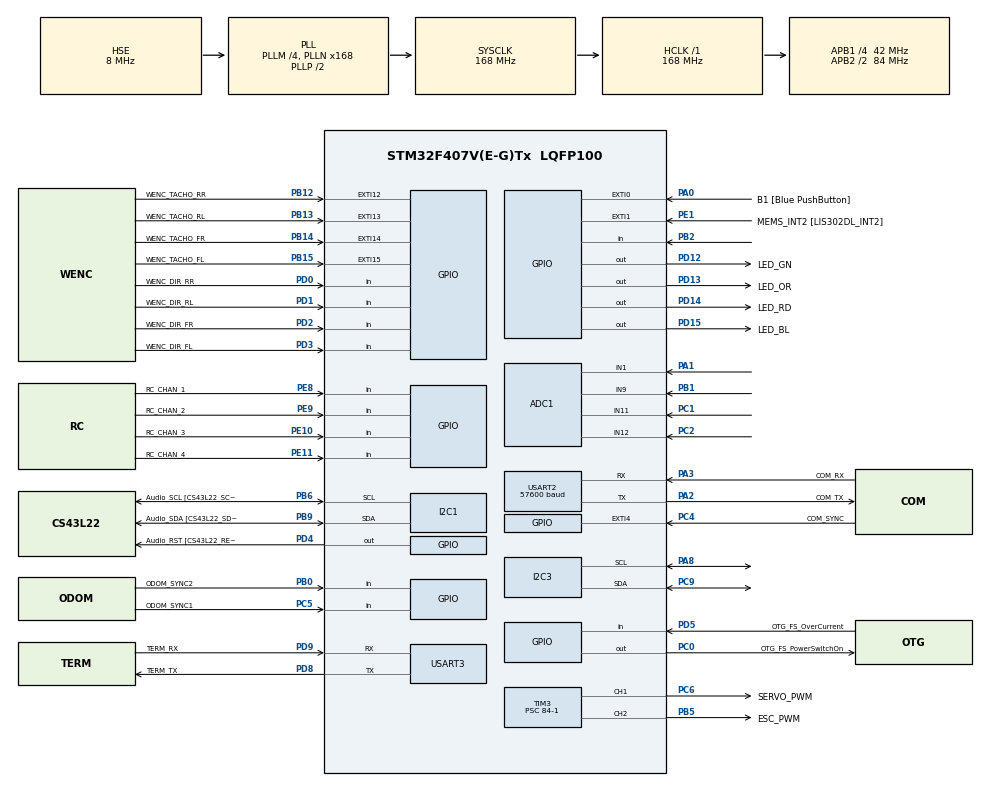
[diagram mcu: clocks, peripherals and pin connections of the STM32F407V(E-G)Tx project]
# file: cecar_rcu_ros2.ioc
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ADC1.Channel-0\#ChannelRegularConversion=ADC_CHANNEL_1
ADC1.NbrOfConversionFlag=1
ADC1.Rank-0\#ChannelRegularConversion=1
ADC1.SamplingTime-0\#ChannelRegularConversion=ADC_SAMPLETIME_3CYCLES
ADC1.master=1
Dma.Request0=USART2_RX
Dma.Request1=USART2_TX
Dma.USART2_RX.0.Direction=DMA_PERIPH_TO_MEMORY
Dma.USART2_RX.0.FIFOMode=DMA_FIFOMODE_DISABLE
Dma.USART2_RX.0.Instance=DMA1_Stream5
Dma.USART2_RX.0.MemDataAlignment=DMA_MDATAALIGN_BYTE
Dma.USART2_RX.0.MemInc=DMA_MINC_ENABLE
Dma.USART2_RX.0.Mode=DMA_CIRCULAR
Dma.USART2_RX.0.PeriphDataAlignment=DMA_PDATAALIGN_BYTE
Dma.USART2_RX.0.PeriphInc=DMA_PINC_DISABLE
Dma.USART2_RX.0.Priority=DMA_PRIORITY_LOW
Dma.USART2_TX.1.Direction=DMA_MEMORY_TO_PERIPH
Dma.USART2_TX.1.FIFOMode=DMA_FIFOMODE_DISABLE
Dma.USART2_TX.1.Instance=DMA1_Stream6
Dma.USART2_TX.1.MemDataAlignment=DMA_MDATAALIGN_BYTE
Dma.USART2_TX.1.MemInc=DMA_MINC_ENABLE
Dma.USART2_TX.1.Mode=DMA_NORMAL
Dma.USART2_TX.1.PeriphDataAlignment=DMA_PDATAALIGN_BYTE
Dma.USART2_TX.1.PeriphInc=DMA_PINC_DISABLE
Dma.USART2_TX.1.Priority=DMA_PRIORITY_LOW
I2C1.I2C_Mode=I2C_Fast
I2C3.I2C_Mode=I2C_Fast
Mcu.Family=STM32F4
Mcu.Name=STM32F407V(E-G)Tx
Mcu.Package=LQFP100
NVIC.DMA1_Stream5_IRQn=true\:0\:0\:false\:false\:true\:false\:true
NVIC.DMA1_Stream6_IRQn=true\:0\:0\:false\:false\:true\:false\:true
NVIC.EXTI15_10_IRQn=true\:0\:0\:false\:false\:true\:true\:true
NVIC.PriorityGroup=NVIC_PRIORITYGROUP_0
NVIC.TIM2_IRQn=true\:0\:0\:false\:false\:true\:true\:true
PA0-WKUP.GPIO_Label=B1 [Blue PushButton]
PA0-WKUP.Signal=GPXTI0
PA1.Signal=ADCx_IN1
PA10.GPIO_Label=OTG_FS_ID
PA10.GPIO_Mode=GPIO_MODE_AF_PP
PA10.GPIO_PuPd=GPIO_NOPULL
PA10.GPIO_Speed=GPIO_SPEED_FREQ_LOW
PA10.Signal=USB_OTG_FS_ID
PA11.GPIO_Label=OTG_FS_DM
PA11.GPIO_Mode=GPIO_MODE_AF_PP
PA11.GPIO_PuPd=GPIO_NOPULL
PA11.GPIO_Speed=GPIO_SPEED_FREQ_LOW
PA11.Signal=USB_OTG_FS_DM
PA12.GPIO_Label=OTG_FS_DP
PA12.GPIO_Mode=GPIO_MODE_AF_PP
PA12.GPIO_PuPd=GPIO_NOPULL
PA12.GPIO_Speed=GPIO_SPEED_FREQ_LOW
PA12.Signal=USB_OTG_FS_DP
PA13.GPIO_Label=SWDIO
PA13.Mode=Trace_Asynchronous_SW
PA13.Signal=SYS_JTMS-SWDIO
PA14.GPIO_Label=SWCLK
PA14.Mode=Trace_Asynchronous_SW
PA14.Signal=SYS_JTCK-SWCLK
PA2.GPIO_Label=COM_TX
PA2.Mode=Asynchronous
PA2.Signal=USART2_TX
PA3.GPIO_Label=COM_RX
PA3.Mode=Asynchronous
PA3.Signal=USART2_RX
PA4.GPIO_Label=I2S3_WS [CS43L22_LRCK]
PA4.GPIO_Mode=GPIO_MODE_AF_PP
PA4.GPIO_PuPd=GPIO_NOPULL
PA4.GPIO_Speed=GPIO_SPEED_FREQ_LOW
PA4.Signal=I2S3_WS
PA5.GPIO_Label=SPI1_SCK [LIS302DL_SCL/SPC]
PA5.GPIO_Mode=GPIO_MODE_AF_PP
PA5.GPIO_PuPd=GPIO_NOPULL
PA5.GPIO_Speed=GPIO_SPEED_FREQ_LOW
PA5.Signal=SPI1_SCK
PA6.GPIO_Label=SPI1_MISO [LIS302DL_SDO]
PA6.GPIO_Mode=GPIO_MODE_AF_PP
PA6.GPIO_PuPd=GPIO_NOPULL
PA6.GPIO_Speed=GPIO_SPEED_FREQ_LOW
PA6.Signal=SPI1_MISO
PA7.GPIO_Label=SPI1_MOSI [LIS302DL_SDA/SDI/SDO]
PA7.GPIO_Mode=GPIO_MODE_AF_PP
PA7.GPIO_PuPd=GPIO_NOPULL
PA7.GPIO_Speed=GPIO_SPEED_FREQ_LOW
PA7.Signal=SPI1_MOSI
PA8.Mode=I2C
PA8.Signal=I2C3_SCL
PA9.GPIO_Label=VBUS_FS
PA9.GPIO_Mode=GPIO_MODE_INPUT
PA9.GPIO_PuPd=GPIO_NOPULL
PA9.Signal=USB_OTG_FS_VBUS
PB0.GPIO_Label=ODOM_SYNC2
PB0.Signal=GPIO_Input
PB1.Signal=ADCx_IN9
PB10.GPIO_Label=CLK_IN [MP45DT02_CLK]
PB10.GPIO_Mode=GPIO_MODE_AF_PP
PB10.GPIO_PuPd=GPIO_NOPULL
PB10.GPIO_Speed=GPIO_SPEED_FREQ_LOW
PB10.Signal=I2S2_CK
PB12.GPIO_Label=WENC_TACHO_RR
PB12.Signal=GPXTI12
PB13.GPIO_Label=WENC_TACHO_RL
PB13.Signal=GPXTI13
PB14.GPIO_Label=WENC_TACHO_FR
PB14.Signal=GPXTI14
PB15.GPIO_Label=WENC_TACHO_FL
PB15.Signal=GPXTI15
PB2.Signal=GPIO_Input
PB3.GPIO_Label=SWO
PB3.Mode=Trace_Asynchronous_SW
PB3.Signal=SYS_JTDO-SWO
PB5.GPIO_Label=ESC_PWM
PB5.Signal=S_TIM3_CH2
PB6.GPIO_Label=Audio_SCL [CS43L22_SCL]
PB6.GPIO_Mode=GPIO_MODE_AF_OD
PB6.GPIO_PuPd=GPIO_NOPULL
PB6.GPIO_Speed=GPIO_SPEED_FREQ_LOW
PB6.Mode=I2C
PB6.Signal=I2C1_SCL
PB9.GPIO_Label=Audio_SDA [CS43L22_SDA]
PB9.GPIO_Mode=GPIO_MODE_AF_OD
PB9.GPIO_PuPd=GPIO_NOPULL
PB9.GPIO_Speed=GPIO_SPEED_FREQ_LOW
PB9.Mode=I2C
PB9.Signal=I2C1_SDA
PC0.GPIO_Label=OTG_FS_PowerSwitchOn
PC0.GPIO_PuPd=GPIO_NOPULL
PC0.GPIO_Speed=GPIO_SPEED_FREQ_LOW
PC0.PinState=GPIO_PIN_SET
PC0.Signal=GPIO_Output
PC1.Signal=ADCx_IN11
PC10.GPIO_Label=I2S3_SCK [CS43L22_SCLK]
PC10.GPIO_Mode=GPIO_MODE_AF_PP
PC10.GPIO_PuPd=GPIO_NOPULL
PC10.GPIO_Speed=GPIO_SPEED_FREQ_LOW
PC10.Signal=I2S3_CK
PC12.GPIO_Label=I2S3_SD [CS43L22_SDIN]
PC12.GPIO_Mode=GPIO_MODE_AF_PP
PC12.GPIO_PuPd=GPIO_NOPULL
PC12.GPIO_Speed=GPIO_SPEED_FREQ_LOW
PC12.Signal=I2S3_SD
PC14-OSC32_IN.GPIO_Label=PC14-OSC32_IN
PC14-OSC32_IN.Signal=RCC_OSC32_IN
PC15-OSC32_OUT.GPIO_Label=PC15-OSC32_OUT
PC15-OSC32_OUT.Signal=RCC_OSC32_OUT
PC2.Signal=ADCx_IN12
PC3.GPIO_Label=PDM_OUT [MP45DT02_DOUT]
PC3.GPIO_Mode=GPIO_MODE_AF_PP
PC3.GPIO_PuPd=GPIO_NOPULL
PC3.GPIO_Speed=GPIO_SPEED_FREQ_LOW
PC3.Signal=I2S2_SD
PC4.GPIO_Label=COM_SYNC
PC4.Signal=GPXTI4
PC5.GPIO_Label=ODOM_SYNC1
PC5.Signal=GPIO_Input
PC6.GPIO_Label=SERVO_PWM
PC6.Signal=S_TIM3_CH1
PC7.GPIO_Label=I2S3_MCK [CS43L22_MCLK]
PC7.GPIO_Mode=GPIO_MODE_AF_PP
PC7.GPIO_PuPd=GPIO_NOPULL
PC7.GPIO_Speed=GPIO_SPEED_FREQ_LOW
PC7.Signal=I2S3_MCK
PC9.Mode=I2C
PC9.Signal=I2C3_SDA
PD0.GPIO_Label=WENC_DIR_RR
PD0.Signal=GPIO_Input
PD1.GPIO_Label=WENC_DIR_RL
PD1.Signal=GPIO_Input
PD12.GPIO_Label=LED_GN
PD12.Signal=GPIO_Output
PD13.GPIO_Label=LED_OR
PD13.Signal=GPIO_Output
PD14.GPIO_Label=LED_RD
PD14.Signal=GPIO_Output
PD15.GPIO_Label=LED_BL
PD15.Signal=GPIO_Output
PD2.GPIO_Label=WENC_DIR_FR
PD2.Signal=GPIO_Input
PD3.GPIO_Label=WENC_DIR_FL
PD3.Signal=GPIO_Input
PD4.GPIO_Label=Audio_RST [CS43L22_RESET]
PD4.GPIO_PuPd=GPIO_NOPULL
PD4.GPIO_Speed=GPIO_SPEED_FREQ_LOW
PD4.Signal=GPIO_Output
PD5.GPIO_Label=OTG_FS_OverCurrent
PD5.GPIO_Mode=GPIO_MODE_INPUT
PD5.GPIO_PuPd=GPIO_NOPULL
PD5.Signal=GPIO_Input
PD8.GPIO_Label=TERM_TX
PD8.Mode=Asynchronous
PD8.Signal=USART3_TX
PD9.GPIO_Label=TERM_RX
PD9.Mode=Asynchronous
PD9.Signal=USART3_RX
PE1.GPIO_Label=MEMS_INT2 [LIS302DL_INT2]
PE1.GPIO_ModeDefaultEXTI=GPIO_MODE_EVT_RISING
PE1.GPIO_PuPd=GPIO_NOPULL
PE1.Signal=GPXTI1
PE10.GPIO_Label=RC_CHAN_3
PE10.Signal=GPIO_Input
PE11.GPIO_Label=RC_CHAN_4
PE11.Signal=GPIO_Input
PE8.GPIO_Label=RC_CHAN_1
PE8.Signal=GPIO_Input
PE9.GPIO_Label=RC_CHAN_2
PE9.Signal=GPIO_Input
PH0-OSC_IN.GPIO_Label=PH0-OSC_IN
PH0-OSC_IN.Mode=HSE-External-Oscillator
PH0-OSC_IN.Signal=RCC_OSC_IN
PH1-OSC_OUT.GPIO_Label=PH1-OSC_OUT
PH1-OSC_OUT.Mode=HSE-External-Oscillator
PH1-OSC_OUT.Signal=RCC_OSC_OUT
ProjectManager.HeapSize=0x200
ProjectManager.StackSize=0x400
ProjectManager.TargetToolchain=STM32CubeIDE
RCC.48MHZClocksFreq_Value=48000000
RCC.AHBFreq_Value=168000000
RCC.APB1CLKDivider=RCC_HCLK_DIV4
RCC.APB1Freq_Value=42000000
RCC.APB1TimFreq_Value=84000000
RCC.APB2CLKDivider=RCC_HCLK_DIV2
RCC.APB2Freq_Value=84000000
RCC.APB2TimFreq_Value=168000000
RCC.CortexFreq_Value=168000000
RCC.HCLKFreq_Value=168000000
RCC.HSE_VALUE=8000000
RCC.HSI_VALUE=16000000
RCC.LSE_VALUE=32768
RCC.PLLM=4
RCC.PLLN=168
RCC.PLLQ=7
RCC.PLLSourceVirtual=RCC_PLLSOURCE_HSE
RCC.SYSCLKFreq_VALUE=168000000
RCC.SYSCLKSource=RCC_SYSCLKSOURCE_PLLCLK
RCC.VCOOutputFreq_Value=336000000
SH.ADCx_IN1.0=ADC1_IN1,IN1
SH.ADCx_IN11.0=ADC1_IN11,IN11
SH.ADCx_IN12.0=ADC1_IN12,IN12
SH.ADCx_IN9.0=ADC1_IN9,IN9
SH.S_TIM3_CH1.0=TIM3_CH1,PWM Generation1 CH1
SH.S_TIM3_CH2.0=TIM3_CH2,PWM Generation2 CH2
TIM2.Channel-Output\ Compare1\ No\ Output=TIM_CHANNEL_1
TIM2.Period=100000-1
TIM2.Prescaler=84-1
TIM2.TIM_MasterOutputTrigger=TIM_TRGO_OC1
TIM2.TIM_MasterSlaveMode=TIM_MASTERSLAVEMODE_ENABLE
TIM3.Channel-PWM\ Generation1\ CH1=TIM_CHANNEL_1
TIM3.Channel-PWM\ Generation2\ CH2=TIM_CHANNEL_2
TIM3.Period=19999
TIM3.Prescaler=84-1
TIM3.Pulse-PWM\ Generation2\ CH2=1500
USART2.BaudRate=57600
USART2.VirtualMode=VM_ASYNC
USART3.VirtualMode=VM_ASYNC
VP_TIM2_VS_ClockSourceINT.Mode=Internal
VP_TIM2_VS_no_output1.Mode=Output Compare1 No Output
board=STM32F407G-DISC1

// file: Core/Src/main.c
/* USER CODE BEGIN Header */
/**
  ******************************************************************************
  * @file           : main.c
  * @brief          : Main program body
  ******************************************************************************
  * @attention
  *
  * <h2><center>&copy; Copyright (c) 2019 STMicroelectronics.
  * All rights reserved.</center></h2>
  *
  * This software component is licensed by ST under BSD 3-Clause license,
  * the "License"; You may not use this file except in compliance with the
  * License. You may obtain a copy of the License at:
  *                        opensource.org/licenses/BSD-3-Clause
  *
  ******************************************************************************
  */
/* USER CODE END Header */

#include "main.h"

/* USER CODE BEGIN Includes */
#include <main_cpp.h>
/* USER CODE END Includes */

ADC_HandleTypeDef hadc1;

I2C_HandleTypeDef hi2c1;
I2C_HandleTypeDef hi2c3;

TIM_HandleTypeDef htim2;
TIM_HandleTypeDef htim3;

UART_HandleTypeDef huart2;
UART_HandleTypeDef huart3;
DMA_HandleTypeDef hdma_usart2_rx;
DMA_HandleTypeDef hdma_usart2_tx;

void SystemClock_Config(void);
static void MX_GPIO_Init(void);
static void MX_DMA_Init(void);
static void MX_ADC1_Init(void);
static void MX_TIM2_Init(void);
static void MX_TIM3_Init(void);
static void MX_USART2_UART_Init(void);
static void MX_USART3_UART_Init(void);
static void MX_I2C1_Init(void);
static void MX_I2C3_Init(void);

/* USER CODE BEGIN 0 */

// for SWO debugging, see http://stefanfrings.de/stm32/cube_ide.html
int __io_putchar(char ch)
{
	return ITM_SendChar(ch);
}
/* USER CODE END 0 */

int main(void)
{
  /* USER CODE BEGIN 1 */
	// for easier timer debugging
#if 0
	__HAL_DBGMCU_FREEZE_TIM1();
	__HAL_DBGMCU_FREEZE_TIM2();
	__HAL_DBGMCU_FREEZE_TIM3();
	__HAL_DBGMCU_FREEZE_TIM4();
#endif
  /* USER CODE END 1 */

  /* MCU Configuration--------------------------------------------------------*/

  /* Reset of all peripherals, Initializes the Flash interface and the Systick. */
  HAL_Init();

  /* Configure the system clock */
  SystemClock_Config();

  /* Initialize all configured peripherals */
  MX_GPIO_Init();
  MX_DMA_Init();
  MX_ADC1_Init();
  MX_TIM2_Init();
  MX_TIM3_Init();
  MX_USART2_UART_Init();
  MX_USART3_UART_Init();
  MX_I2C1_Init();
  MX_I2C3_Init();
  /* USER CODE BEGIN 2 */
  setup(&huart2);
  /* USER CODE END 2 */

  /* Infinite loop */
  /* USER CODE BEGIN WHILE */
  while (1)
  {
	  loop(&huart2, &hdma_usart2_rx);
    /* USER CODE END WHILE */

  }
}

void SystemClock_Config(void)
{
  RCC_OscInitTypeDef RCC_OscInitStruct = {0};
  RCC_ClkInitTypeDef RCC_ClkInitStruct = {0};

  /** Configure the main internal regulator output voltage
  */
  __HAL_RCC_PWR_CLK_ENABLE();
  __HAL_PWR_VOLTAGESCALING_CONFIG(PWR_REGULATOR_VOLTAGE_SCALE1);
  /** Initializes the CPU, AHB and APB busses clocks
  */
  RCC_OscInitStruct.OscillatorType = RCC_OSCILLATORTYPE_HSE;
  RCC_OscInitStruct.HSEState = RCC_HSE_ON;
  RCC_OscInitStruct.PLL.PLLState = RCC_PLL_ON;
  RCC_OscInitStruct.PLL.PLLSource = RCC_PLLSOURCE_HSE;
  RCC_OscInitStruct.PLL.PLLM = 4;
  RCC_OscInitStruct.PLL.PLLN = 168;
  RCC_OscInitStruct.PLL.PLLP = RCC_PLLP_DIV2;
  RCC_OscInitStruct.PLL.PLLQ = 7;
  if (HAL_RCC_OscConfig(&RCC_OscInitStruct) != HAL_OK)
  {
    Error_Handler();
  }
  /** Initializes the CPU, AHB and APB busses clocks
  */
  RCC_ClkInitStruct.ClockType = RCC_CLOCKTYPE_HCLK|RCC_CLOCKTYPE_SYSCLK
                              |RCC_CLOCKTYPE_PCLK1|RCC_CLOCKTYPE_PCLK2;
  RCC_ClkInitStruct.SYSCLKSource = RCC_SYSCLKSOURCE_PLLCLK;
  RCC_ClkInitStruct.AHBCLKDivider = RCC_SYSCLK_DIV1;
  RCC_ClkInitStruct.APB1CLKDivider = RCC_HCLK_DIV4;
  RCC_ClkInitStruct.APB2CLKDivider = RCC_HCLK_DIV2;

  if (HAL_RCC_ClockConfig(&RCC_ClkInitStruct, FLASH_LATENCY_5) != HAL_OK)
  {
    Error_Handler();
  }
}

static void MX_ADC1_Init(void)
{

  ADC_ChannelConfTypeDef sConfig = {0};

  /** Configure the global features of the ADC (Clock, Resolution, Data Alignment and number of conversion)
  */
  hadc1.Instance = ADC1;
  hadc1.Init.ClockPrescaler = ADC_CLOCK_SYNC_PCLK_DIV4;
  hadc1.Init.Resolution = ADC_RESOLUTION_12B;
  hadc1.Init.ScanConvMode = DISABLE;
  hadc1.Init.ContinuousConvMode = DISABLE;
  hadc1.Init.DiscontinuousConvMode = DISABLE;
  hadc1.Init.ExternalTrigConvEdge = ADC_EXTERNALTRIGCONVEDGE_NONE;
  hadc1.Init.ExternalTrigConv = ADC_SOFTWARE_START;
  hadc1.Init.DataAlign = ADC_DATAALIGN_RIGHT;
  hadc1.Init.NbrOfConversion = 1;
  hadc1.Init.DMAContinuousRequests = DISABLE;
  hadc1.Init.EOCSelection = ADC_EOC_SINGLE_CONV;
  if (HAL_ADC_Init(&hadc1) != HAL_OK)
  {
    Error_Handler();
  }
  /** Configure for the selected ADC regular channel its corresponding rank in the sequencer and its sample time.
  */
  sConfig.Channel = ADC_CHANNEL_1;
  sConfig.Rank = 1;
  sConfig.SamplingTime = ADC_SAMPLETIME_3CYCLES;
  if (HAL_ADC_ConfigChannel(&hadc1, &sConfig) != HAL_OK)
  {
    Error_Handler();
  }

}

static void MX_I2C1_Init(void)
{

  hi2c1.Instance = I2C1;
  hi2c1.Init.ClockSpeed = 400000;
  hi2c1.Init.DutyCycle = I2C_DUTYCYCLE_2;
  hi2c1.Init.OwnAddress1 = 0;
  hi2c1.Init.AddressingMode = I2C_ADDRESSINGMODE_7BIT;
  hi2c1.Init.DualAddressMode = I2C_DUALADDRESS_DISABLE;
  hi2c1.Init.OwnAddress2 = 0;
  hi2c1.Init.GeneralCallMode = I2C_GENERALCALL_DISABLE;
  hi2c1.Init.NoStretchMode = I2C_NOSTRETCH_DISABLE;
  if (HAL_I2C_Init(&hi2c1) != HAL_OK)
  {
    Error_Handler();
  }

}

static void MX_I2C3_Init(void)
{

  hi2c3.Instance = I2C3;
  hi2c3.Init.ClockSpeed = 400000;
  hi2c3.Init.DutyCycle = I2C_DUTYCYCLE_2;
  hi2c3.Init.OwnAddress1 = 0;
  hi2c3.Init.AddressingMode = I2C_ADDRESSINGMODE_7BIT;
  hi2c3.Init.DualAddressMode = I2C_DUALADDRESS_DISABLE;
  hi2c3.Init.OwnAddress2 = 0;
  hi2c3.Init.GeneralCallMode = I2C_GENERALCALL_DISABLE;
  hi2c3.Init.NoStretchMode = I2C_NOSTRETCH_DISABLE;
  if (HAL_I2C_Init(&hi2c3) != HAL_OK)
  {
    Error_Handler();
  }

}

static void MX_TIM2_Init(void)
{

  TIM_ClockConfigTypeDef sClockSourceConfig = {0};
  TIM_MasterConfigTypeDef sMasterConfig = {0};
  TIM_OC_InitTypeDef sConfigOC = {0};

  htim2.Instance = TIM2;
  htim2.Init.Prescaler = 84-1;
  htim2.Init.CounterMode = TIM_COUNTERMODE_UP;
  htim2.Init.Period = 100000-1;
  htim2.Init.ClockDivision = TIM_CLOCKDIVISION_DIV1;
  htim2.Init.AutoReloadPreload = TIM_AUTORELOAD_PRELOAD_DISABLE;
  if (HAL_TIM_Base_Init(&htim2) != HAL_OK)
  {
    Error_Handler();
  }
  sClockSourceConfig.ClockSource = TIM_CLOCKSOURCE_INTERNAL;
  if (HAL_TIM_ConfigClockSource(&htim2, &sClockSourceConfig) != HAL_OK)
  {
    Error_Handler();
  }
  if (HAL_TIM_OC_Init(&htim2) != HAL_OK)
  {
    Error_Handler();
  }
  sMasterConfig.MasterOutputTrigger = TIM_TRGO_OC1;
  sMasterConfig.MasterSlaveMode = TIM_MASTERSLAVEMODE_ENABLE;
  if (HAL_TIMEx_MasterConfigSynchronization(&htim2, &sMasterConfig) != HAL_OK)
  {
    Error_Handler();
  }
  sConfigOC.OCMode = TIM_OCMODE_TIMING;
  sConfigOC.Pulse = 0;
  sConfigOC.OCPolarity = TIM_OCPOLARITY_HIGH;
  sConfigOC.OCFastMode = TIM_OCFAST_DISABLE;
  if (HAL_TIM_OC_ConfigChannel(&htim2, &sConfigOC, TIM_CHANNEL_1) != HAL_OK)
  {
    Error_Handler();
  }

}

static void MX_TIM3_Init(void)
{

  TIM_MasterConfigTypeDef sMasterConfig = {0};
  TIM_OC_InitTypeDef sConfigOC = {0};

  htim3.Instance = TIM3;
  htim3.Init.Prescaler = 84-1;
  htim3.Init.CounterMode = TIM_COUNTERMODE_UP;
  htim3.Init.Period = 19999;
  htim3.Init.ClockDivision = TIM_CLOCKDIVISION_DIV1;
  htim3.Init.AutoReloadPreload = TIM_AUTORELOAD_PRELOAD_DISABLE;
  if (HAL_TIM_PWM_Init(&htim3) != HAL_OK)
  {
    Error_Handler();
  }
  sMasterConfig.MasterOutputTrigger = TIM_TRGO_RESET;
  sMasterConfig.MasterSlaveMode = TIM_MASTERSLAVEMODE_DISABLE;
  if (HAL_TIMEx_MasterConfigSynchronization(&htim3, &sMasterConfig) != HAL_OK)
  {
    Error_Handler();
  }
  sConfigOC.OCMode = TIM_OCMODE_PWM1;
  sConfigOC.Pulse = 0;
  sConfigOC.OCPolarity = TIM_OCPOLARITY_HIGH;
  sConfigOC.OCFastMode = TIM_OCFAST_DISABLE;
  if (HAL_TIM_PWM_ConfigChannel(&htim3, &sConfigOC, TIM_CHANNEL_1) != HAL_OK)
  {
    Error_Handler();
  }
  sConfigOC.Pulse = 1500;
  if (HAL_TIM_PWM_ConfigChannel(&htim3, &sConfigOC, TIM_CHANNEL_2) != HAL_OK)
  {
    Error_Handler();
  }
  HAL_TIM_MspPostInit(&htim3);

}

static void MX_USART2_UART_Init(void)
{

  huart2.Instance = USART2;
  huart2.Init.BaudRate = 57600;
  huart2.Init.WordLength = UART_WORDLENGTH_8B;
  huart2.Init.StopBits = UART_STOPBITS_1;
  huart2.Init.Parity = UART_PARITY_NONE;
  huart2.Init.Mode = UART_MODE_TX_RX;
  huart2.Init.HwFlowCtl = UART_HWCONTROL_NONE;
  huart2.Init.OverSampling = UART_OVERSAMPLING_16;
  if (HAL_UART_Init(&huart2) != HAL_OK)
  {
    Error_Handler();
  }
  /* USER CODE BEGIN USART2_Init 2 */
  __HAL_UART_ENABLE_IT(&huart2, UART_IT_IDLE); /*Enable idle interrupt for UART2*/
  /* USER CODE END USART2_Init 2 */

}

static void MX_USART3_UART_Init(void)
{

  huart3.Instance = USART3;
  huart3.Init.BaudRate = 115200;
  huart3.Init.WordLength = UART_WORDLENGTH_8B;
  huart3.Init.StopBits = UART_STOPBITS_1;
  huart3.Init.Parity = UART_PARITY_NONE;
  huart3.Init.Mode = UART_MODE_TX_RX;
  huart3.Init.HwFlowCtl = UART_HWCONTROL_NONE;
  huart3.Init.OverSampling = UART_OVERSAMPLING_16;
  if (HAL_UART_Init(&huart3) != HAL_OK)
  {
    Error_Handler();
  }

}

static void MX_DMA_Init(void)
{

  /* DMA controller clock enable */
  __HAL_RCC_DMA1_CLK_ENABLE();

  /* DMA interrupt init */
  /* DMA1_Stream5_IRQn interrupt configuration */
  HAL_NVIC_SetPriority(DMA1_Stream5_IRQn, 0, 0);
  HAL_NVIC_EnableIRQ(DMA1_Stream5_IRQn);
  /* DMA1_Stream6_IRQn interrupt configuration */
  HAL_NVIC_SetPriority(DMA1_Stream6_IRQn, 0, 0);
  HAL_NVIC_EnableIRQ(DMA1_Stream6_IRQn);

}

static void MX_GPIO_Init(void)
{
  GPIO_InitTypeDef GPIO_InitStruct = {0};

  /* GPIO Ports Clock Enable */
  __HAL_RCC_GPIOC_CLK_ENABLE();
  __HAL_RCC_GPIOH_CLK_ENABLE();
  __HAL_RCC_GPIOA_CLK_ENABLE();
  __HAL_RCC_GPIOB_CLK_ENABLE();
  __HAL_RCC_GPIOE_CLK_ENABLE();
  __HAL_RCC_GPIOD_CLK_ENABLE();

  /*Configure GPIO pin Output Level */
  HAL_GPIO_WritePin(OTG_FS_PowerSwitchOn_GPIO_Port, OTG_FS_PowerSwitchOn_Pin, GPIO_PIN_SET);

  /*Configure GPIO pin Output Level */
  HAL_GPIO_WritePin(GPIOD, LED_GN_Pin|LED_OR_Pin|LED_RD_Pin|LED_BL_Pin
                          |Audio_RST_Pin, GPIO_PIN_RESET);

  /*Configure GPIO pin : OTG_FS_PowerSwitchOn_Pin */
  GPIO_InitStruct.Pin = OTG_FS_PowerSwitchOn_Pin;
  GPIO_InitStruct.Mode = GPIO_MODE_OUTPUT_PP;
  GPIO_InitStruct.Pull = GPIO_NOPULL;
  GPIO_InitStruct.Speed = GPIO_SPEED_FREQ_LOW;
  HAL_GPIO_Init(OTG_FS_PowerSwitchOn_GPIO_Port, &GPIO_InitStruct);

  /*Configure GPIO pin : PDM_OUT_Pin */
  GPIO_InitStruct.Pin = PDM_OUT_Pin;
  GPIO_InitStruct.Mode = GPIO_MODE_AF_PP;
  GPIO_InitStruct.Pull = GPIO_NOPULL;
  GPIO_InitStruct.Speed = GPIO_SPEED_FREQ_LOW;
  GPIO_InitStruct.Alternate = GPIO_AF5_SPI2;
  HAL_GPIO_Init(PDM_OUT_GPIO_Port, &GPIO_InitStruct);

  /*Configure GPIO pin : B1_Pin */
  GPIO_InitStruct.Pin = B1_Pin;
  GPIO_InitStruct.Mode = GPIO_MODE_IT_RISING;
  GPIO_InitStruct.Pull = GPIO_NOPULL;
  HAL_GPIO_Init(B1_GPIO_Port, &GPIO_InitStruct);

  /*Configure GPIO pin : I2S3_WS_Pin */
  GPIO_InitStruct.Pin = I2S3_WS_Pin;
  GPIO_InitStruct.Mode = GPIO_MODE_AF_PP;
  GPIO_InitStruct.Pull = GPIO_NOPULL;
  GPIO_InitStruct.Speed = GPIO_SPEED_FREQ_LOW;
  GPIO_InitStruct.Alternate = GPIO_AF6_SPI3;
  HAL_GPIO_Init(I2S3_WS_GPIO_Port, &GPIO_InitStruct);

  /*Configure GPIO pins : SPI1_SCK_Pin SPI1_MISO_Pin SPI1_MOSI_Pin */
  GPIO_InitStruct.Pin = SPI1_SCK_Pin|SPI1_MISO_Pin|SPI1_MOSI_Pin;
  GPIO_InitStruct.Mode = GPIO_MODE_AF_PP;
  GPIO_InitStruct.Pull = GPIO_NOPULL;
  GPIO_InitStruct.Speed = GPIO_SPEED_FREQ_LOW;
  GPIO_InitStruct.Alternate = GPIO_AF5_SPI1;
  HAL_GPIO_Init(GPIOA, &GPIO_InitStruct);

  /*Configure GPIO pin : COM_SYNC_Pin */
  GPIO_InitStruct.Pin = COM_SYNC_Pin;
  GPIO_InitStruct.Mode = GPIO_MODE_IT_RISING;
  GPIO_InitStruct.Pull = GPIO_NOPULL;
  HAL_GPIO_Init(COM_SYNC_GPIO_Port, &GPIO_InitStruct);

  /*Configure GPIO pin : ODOM_SYNC1_Pin */
  GPIO_InitStruct.Pin = ODOM_SYNC1_Pin;
  GPIO_InitStruct.Mode = GPIO_MODE_INPUT;
  GPIO_InitStruct.Pull = GPIO_NOPULL;
  HAL_GPIO_Init(ODOM_SYNC1_GPIO_Port, &GPIO_InitStruct);

  /*Configure GPIO pins : ODOM_SYNC2_Pin PB2 */
  GPIO_InitStruct.Pin = ODOM_SYNC2_Pin|GPIO_PIN_2;
  GPIO_InitStruct.Mode = GPIO_MODE_INPUT;
  GPIO_InitStruct.Pull = GPIO_NOPULL;
  HAL_GPIO_Init(GPIOB, &GPIO_InitStruct);

  /*Configure GPIO pins : RC_CHAN_1_Pin RC_CHAN_2_Pin RC_CHAN_3_Pin RC_CHAN_4_Pin */
  GPIO_InitStruct.Pin = RC_CHAN_1_Pin|RC_CHAN_2_Pin|RC_CHAN_3_Pin|RC_CHAN_4_Pin;
  GPIO_InitStruct.Mode = GPIO_MODE_INPUT;
  GPIO_InitStruct.Pull = GPIO_NOPULL;
  HAL_GPIO_Init(GPIOE, &GPIO_InitStruct);

  /*Configure GPIO pin : CLK_IN_Pin */
  GPIO_InitStruct.Pin = CLK_IN_Pin;
  GPIO_InitStruct.Mode = GPIO_MODE_AF_PP;
  GPIO_InitStruct.Pull = GPIO_NOPULL;
  GPIO_InitStruct.Speed = GPIO_SPEED_FREQ_LOW;
  GPIO_InitStruct.Alternate = GPIO_AF5_SPI2;
  HAL_GPIO_Init(CLK_IN_GPIO_Port, &GPIO_InitStruct);

  /*Configure GPIO pins : WENC_TACHO_RR_Pin WENC_TACHO_RL_Pin WENC_TACHO_FR_Pin WENC_TACHO_FL_Pin */
  GPIO_InitStruct.Pin = WENC_TACHO_RR_Pin|WENC_TACHO_RL_Pin|WENC_TACHO_FR_Pin|WENC_TACHO_FL_Pin;
  GPIO_InitStruct.Mode = GPIO_MODE_IT_RISING;
  GPIO_InitStruct.Pull = GPIO_NOPULL;
  HAL_GPIO_Init(GPIOB, &GPIO_InitStruct);

  /*Configure GPIO pins : LED_GN_Pin LED_OR_Pin LED_RD_Pin LED_BL_Pin
                           Audio_RST_Pin */
  GPIO_InitStruct.Pin = LED_GN_Pin|LED_OR_Pin|LED_RD_Pin|LED_BL_Pin
                          |Audio_RST_Pin;
  GPIO_InitStruct.Mode = GPIO_MODE_OUTPUT_PP;
  GPIO_InitStruct.Pull = GPIO_NOPULL;
  GPIO_InitStruct.Speed = GPIO_SPEED_FREQ_LOW;
  HAL_GPIO_Init(GPIOD, &GPIO_InitStruct);

  /*Configure GPIO pins : I2S3_MCK_Pin I2S3_SCK_Pin I2S3_SD_Pin */
  GPIO_InitStruct.Pin = I2S3_MCK_Pin|I2S3_SCK_Pin|I2S3_SD_Pin;
  GPIO_InitStruct.Mode = GPIO_MODE_AF_PP;
  GPIO_InitStruct.Pull = GPIO_NOPULL;
  GPIO_InitStruct.Speed = GPIO_SPEED_FREQ_LOW;
  GPIO_InitStruct.Alternate = GPIO_AF6_SPI3;
  HAL_GPIO_Init(GPIOC, &GPIO_InitStruct);

  /*Configure GPIO pin : VBUS_FS_Pin */
  GPIO_InitStruct.Pin = VBUS_FS_Pin;
  GPIO_InitStruct.Mode = GPIO_MODE_INPUT;
  GPIO_InitStruct.Pull = GPIO_NOPULL;
  HAL_GPIO_Init(VBUS_FS_GPIO_Port, &GPIO_InitStruct);

  /*Configure GPIO pins : OTG_FS_ID_Pin OTG_FS_DM_Pin OTG_FS_DP_Pin */
  GPIO_InitStruct.Pin = OTG_FS_ID_Pin|OTG_FS_DM_Pin|OTG_FS_DP_Pin;
  GPIO_InitStruct.Mode = GPIO_MODE_AF_PP;
  GPIO_InitStruct.Pull = GPIO_NOPULL;
  GPIO_InitStruct.Speed = GPIO_SPEED_FREQ_LOW;
  GPIO_InitStruct.Alternate = GPIO_AF10_OTG_FS;
  HAL_GPIO_Init(GPIOA, &GPIO_InitStruct);

  /*Configure GPIO pins : WENC_DIR_RR_Pin WENC_DIR_RL_Pin WENC_DIR_FR_Pin WENC_DIR_FL_Pin
                           OTG_FS_OverCurrent_Pin */
  GPIO_InitStruct.Pin = WENC_DIR_RR_Pin|WENC_DIR_RL_Pin|WENC_DIR_FR_Pin|WENC_DIR_FL_Pin
                          |OTG_FS_OverCurrent_Pin;
  GPIO_InitStruct.Mode = GPIO_MODE_INPUT;
  GPIO_InitStruct.Pull = GPIO_NOPULL;
  HAL_GPIO_Init(GPIOD, &GPIO_InitStruct);

  /*Configure GPIO pin : MEMS_INT2_Pin */
  GPIO_InitStruct.Pin = MEMS_INT2_Pin;
  GPIO_InitStruct.Mode = GPIO_MODE_EVT_RISING;
  GPIO_InitStruct.Pull = GPIO_NOPULL;
  HAL_GPIO_Init(MEMS_INT2_GPIO_Port, &GPIO_InitStruct);

  /* EXTI interrupt init*/
  HAL_NVIC_SetPriority(EXTI15_10_IRQn, 0, 0);
  HAL_NVIC_EnableIRQ(EXTI15_10_IRQn);

}

void Error_Handler(void)
{
}

/************************ (C) COPYRIGHT STMicroelectronics *****END OF FILE****/
